# SEMAPHORE register map
Vendor: Texas Instruments
Peripheral module from a debugger description file (folder 66AK2G0x_66AK2G1x).
Registers are 32-bit, access per field, reset 0x1 unless marked. A register's access mark holds for its fields unless they carry their own. Offsets are as the file gives them; lines under a group give offsets from that group; [hi:lo] are bit positions; {n}, {i} and the like mark numbered series; 'fields as' and 'values as' point back to an identical list; <NAME> marks a mode.

## SEMAPHORE
0x00 SEM_PID ro reset 0x48021A00
  [31:0] REV — TI internal data. Identifies revision of peripheral.
0x08 SEM_RST_RUN reset 0x0
  [0] RESET rw — Reset bit 0h (R) = Module is not ready. 0h (W) = No affect. 1h (R) = Module ready. 1h (W) = Resets the module.
0x0C SEM_EOI reset 0x0
  [7:0] EOI wo — Interrupt End of Interrupt 0h (W) = Re-arm SEM_INT0. 1h (W) = Re-arm SEM_INT1. ... 10h (W) = Re-arm
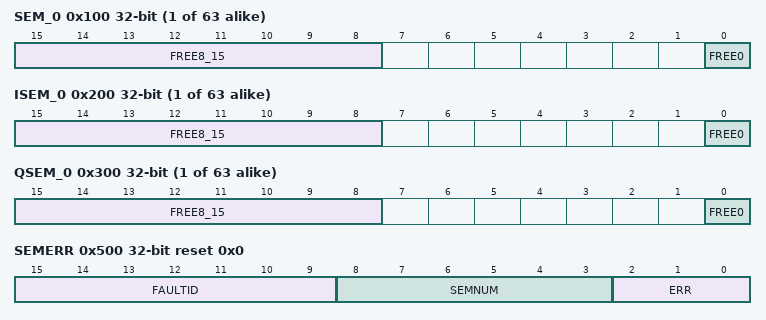
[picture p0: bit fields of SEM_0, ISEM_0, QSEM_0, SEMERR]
{0x100+4i} SEM_{i} (i=0..62)
  [15:8] FREE8_15 ro — Semaphore resource owner FREE0 = 0h: Read returns Core ID of current owner FREE0 = 1h: Read returns 0h.
  [0] FREE0 rw — Direct Semaphore flag control, read/write action 0h (R) = Semaphore is not granted. 0h (W) = Request posted to queue. 1h (R) = Semaphore is granted to the reader. 1h (W) = Semaphore is set free
{0x200+4i} ISEM_{i} (i=0..62)
  [15:8] FREE8_15 ro — Semaphore resource owner FREE0 = 0h: Read returns Core ID of current owner FREE0 = 1h: Read returns 0h.
  [0] FREE0 rw — Indirect Semaphore flag control, read/write action 0h (R) = Semaphore is not granted, request posted to queue. 0h (W) = Request posted to queue. 1h (R) = Semaphore is granted to the reader. 1h (W) = Semaphore is set free
{0x300+4i} QSEM_{i} (i=0..62)
  [15:8] FREE8_15 ro — Semaphore resource owner FREE0 = 0h: Read returns Core ID of current owner FREE0 = 1h: Read returns 0h.
  [0] FREE0 rw — Semaphore flag query and control, read/write action 0h (R) = Semaphore is not available. 0h (W) = Request posted to queue. 1h (R) = Semaphore is available. 1h (W) = Semaphore is set free
{0x400+4i} SEMFLAGL_{i} ro reset 0x0 (i=0..14)
  [31:0] Fn — Semaphore flag n 0h (R) = No interrupt generated to core-m. 1h (R) = Interrupt was generated core-m to signal that semaphore-n was granted to it.
{0x400+4i} SEMFLAGL_CLEAR_{i} wo reset 0x0 (i=0..14)
  [31:0] Fn — Semaphore Flag Clear n 0h (W) = No effect. 1h (W) = Flag bit n is cleared.
{0x440+4i} SEMFLAGH_{i} ro reset 0x0 (i=0..14)
  fields as SEMFLAGL_0
{0x440+4i} SEMFLAGH_CLEAR_{i} wo reset 0x0 (i=0..14)
  fields as SEMFLAGL_CLEAR_0
{0x480+4i} SEMFLAGL_SET_{i} wo reset 0x0 (i=0..14)
  [31:0] Fn — Semaphore Flag Set n 0h (W) = No effect. 1h (W) = Flag bit n is set, SEM_INTx is generated.
{0x4C0+4i} SEMFLAGH_SET_{i} wo reset 0x0 (i=0..14)
  fields as SEMFLAGL_SET_0
0x500 SEMERR ro reset 0x0
  [15:9] FAULTID — Master that caused the error Read returns ID of the core that is responsible for the error (0h-Fh).
  [8:3] SEMNUM — Semaphore Number Read returns Semaphore number associated with error (0h-3Fh).
  [2:0] ERR — Semaphore Error Code 0h (R) = No Error. 1h (R) = Already Free Error. 2h (R) = Illegal Free Error. 3h (R) = Already Own Error. 4h (R) = Already Requested Error.
0x504 SEMERR_CLEAR reset 0x0
  [0] CLRERR wo — Clear Semaphore Error 0h (W) = No effect. 1h (W) = Clears the
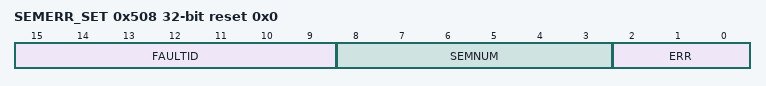
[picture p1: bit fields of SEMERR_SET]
0x508 SEMERR_SET reset 0x0
  [15:9] FAULTID wo — Set Master that caused the error ID of the core that will be responsible for the error (0h-Fh).
  [8:3] SEMNUM wo — Set Semaphore Number Semaphore number associated with error (0h-3Fh).
  [2:0] ERR wo — Set Semaphore error code 0h (W) = No Error. 1h (W) = Already Free Error. 2h (W) = Illegal Free Error. 3h (W) = Already Own Error. 4h (W) = Already Requested Error.
